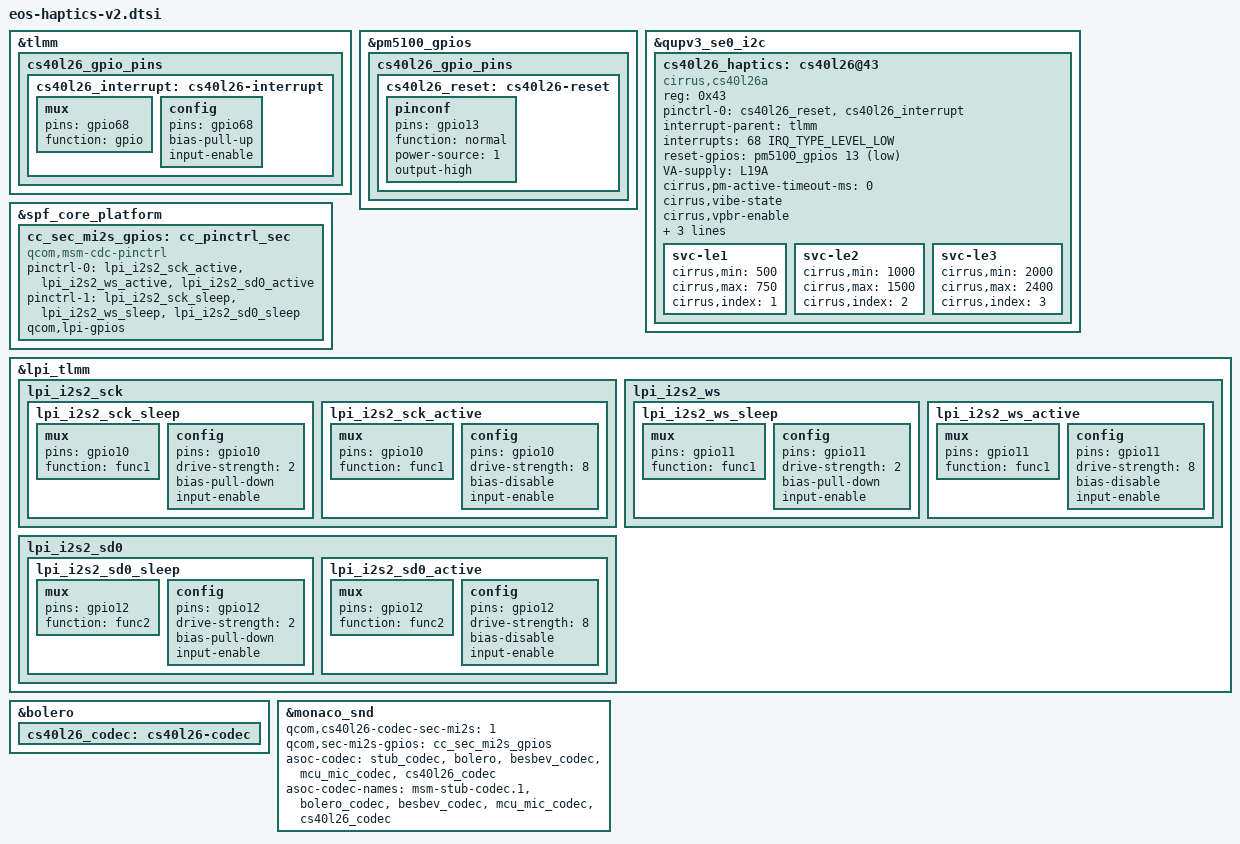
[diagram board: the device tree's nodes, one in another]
// SPDX-License-Identifier: GPL-2.0

#include <dt-bindings/interrupt-controller/irq.h>

&tlmm {
	cs40l26_gpio_pins {
		cs40l26_interrupt: cs40l26-interrupt {
			mux {
				pins = "gpio68";
				function = "gpio";
			};

			config {
				pins = "gpio68";
				bias-pull-up;
				input-enable;
			};
		};
	};
};

&pm5100_gpios {
	cs40l26_gpio_pins {
		cs40l26_reset: cs40l26-reset {
			pinconf {
				pins = "gpio13";
				function = "normal";
				power-source = <1>; /* VREG_L19A */
				output-high;
			};
		};
	};
};

&qupv3_se0_i2c {
	#address-cells = <1>;
	#size-cells = <0>;

	status = "ok";

	cs40l26_haptics: cs40l26@43 {
		compatible = "cirrus,cs40l26a";
		reg = <0x43>;
		pinctrl-names = "default";
		pinctrl-0 = <&cs40l26_reset>, <&cs40l26_interrupt>;
		interrupt-parent = <&tlmm>;
		interrupts = <68 IRQ_TYPE_LEVEL_LOW>;
		reset-gpios = <&pm5100_gpios 13 GPIO_ACTIVE_LOW>;
		VA-supply = <&L19A>;

		cirrus,pm-active-timeout-ms=<0>;

		cirrus,vibe-state;

		cirrus,vpbr-enable;
		cirrus,vpbr-thld-mv = <2592>;

		cirrus,disable-a2h;
		cirrus,disable-dvl;

		svc-le1 {
			cirrus,min = <500>; //59.6 uH
			cirrus,max = <750>; //89.4 uH
			cirrus,index = <1>;
		};
		svc-le2 {
			cirrus,min = <1000>; //119.2 uH
			cirrus,max = <1500>; //178.8 uH
			cirrus,index = <2>;
		};
		svc-le3 {
			cirrus,min = <2000>; //238.4 uH
			cirrus,max = <2400>; //286.1 uH
			cirrus,index = <3>;
		};
	};
};

&spf_core_platform {
	cc_sec_mi2s_gpios: cc_pinctrl_sec {
		compatible = "qcom,msm-cdc-pinctrl";
		pinctrl-names = "aud_active", "aud_sleep";
		pinctrl-0 = <&lpi_i2s2_sck_active &lpi_i2s2_ws_active
				&lpi_i2s2_sd0_active>;

		pinctrl-1 = <&lpi_i2s2_sck_sleep &lpi_i2s2_ws_sleep
				&lpi_i2s2_sd0_sleep>;
		qcom,lpi-gpios;
		#gpio-cells = <0>;
	};
};

&lpi_tlmm {
	lpi_i2s2_sck {
		lpi_i2s2_sck_sleep: lpi_i2s2_sck_sleep {
			mux {
				pins = "gpio10";
				function = "func1";
			};

			config {
				pins = "gpio10";
				drive-strength = <2>;   /* 2 mA */
				bias-pull-down;         /* PULL DOWN */
				input-enable;
			};
		};

		lpi_i2s2_sck_active: lpi_i2s2_sck_active {
			mux {
				pins = "gpio10";
				function = "func1";
			};

			config {
				pins = "gpio10";
				drive-strength = <8>;   /* 8 mA */
				bias-disable;           /* NO PULL */
				input-enable;
			};
		};
	};

	lpi_i2s2_ws {
		lpi_i2s2_ws_sleep: lpi_i2s2_ws_sleep {
			mux {
				pins = "gpio11";
				function = "func1";
			};

			config {
				pins = "gpio11";
				drive-strength = <2>;   /* 2 mA */
				bias-pull-down;         /* PULL DOWN */
				input-enable;
			};
		};

		lpi_i2s2_ws_active: lpi_i2s2_ws_active {
			mux {
				pins = "gpio11";
				function = "func1";
			};

			config {
				pins = "gpio11";
				drive-strength = <8>;   /* 8 mA */
				bias-disable;           /* NO PULL */
				input-enable;
			};
		};
	};

	lpi_i2s2_sd0 {
		lpi_i2s2_sd0_sleep: lpi_i2s2_sd0_sleep {
			mux {
				pins = "gpio12";
				function = "func2";
			};

			config {
				pins = "gpio12";
				drive-strength = <2>;   /* 2 mA */
				bias-pull-down;         /* PULL DOWN */
				input-enable;
			};
		};

		lpi_i2s2_sd0_active: lpi_i2s2_sd0_active {
			mux {
				pins = "gpio12";
				function = "func2";
			};

			config {
				pins = "gpio12";
				drive-strength = <8>;   /* 8 mA */
				bias-disable;           /* NO PULL */
				input-enable;
			};
		};
	};
};

&bolero {
	cs40l26_codec: cs40l26-codec {
		status = "ok";
	};
};

&monaco_snd {
	qcom,cs40l26-codec-sec-mi2s = <1>;
	qcom,sec-mi2s-gpios = <&cc_sec_mi2s_gpios>;

	asoc-codec  = <&stub_codec>, <&bolero>,
			<&besbev_codec>, <&mcu_mic_codec>, <&cs40l26_codec>;
	asoc-codec-names = "msm-stub-codec.1", "bolero_codec",
				"besbev_codec", "mcu_mic_codec", "cs40l26_codec";
};
